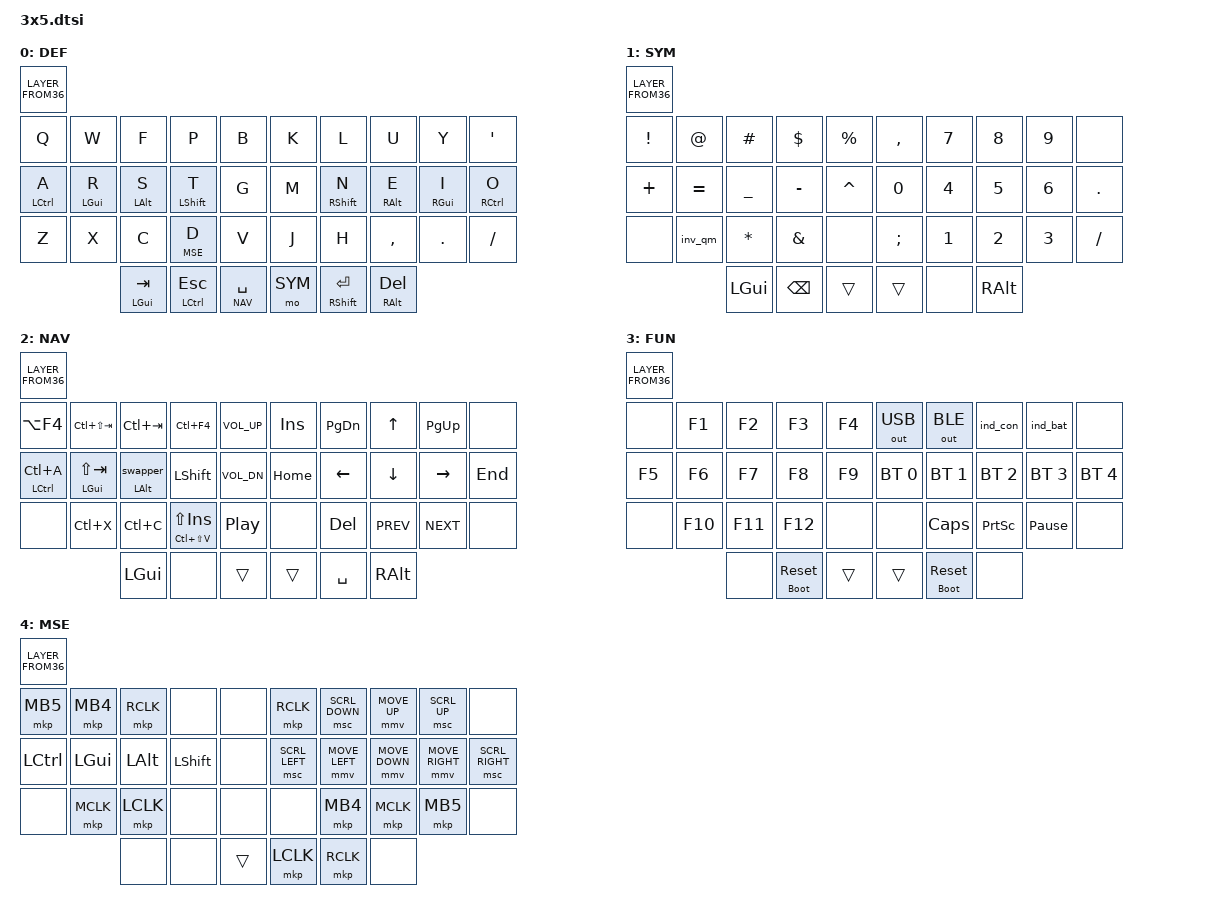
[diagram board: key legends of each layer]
#include <behaviors.dtsi>
#include <dt-bindings/zmk/keys.h>
#include <dt-bindings/zmk/bt.h>
#include <dt-bindings/zmk/outputs.h>

#include <behaviors/rgbled_widget.dtsi>

// Layer aliases
#define DEF 0
#define SYM 1
#define NAV 2
#define FUN 3
#define MSE 4

#include "combos.dtsi"

#include "mouse.dtsi"

&mt {
    flavor = "hold-preferred";
    tapping-term-ms = <150>;
};

&lt {
    flavor = "balanced";
    tapping-term-ms = <150>;
};

&caps_word {
    continue-list = <UNDERSCORE MINUS BSPC DEL N1 N2 N3 N4 N5 N6 N7 N8 N9 N0>;
};

/ {
    behaviors {
        aml: alpha_mods_l {
            compatible = "zmk,behavior-hold-tap";
            #binding-cells = <2>;
            tapping-term-ms = <250>;
            quick-tap-ms = <150>;
            flavor = "balanced";
            bindings = <&kp>, <&kp>;
            hold-trigger-key-positions = <KEYS_R THUMBS>;
            hold-trigger-on-release;
            require-prior-idle-ms = <175>;
        };
        asl: alpha_shift_l {
            compatible = "zmk,behavior-hold-tap";
            #binding-cells = <2>;
            tapping-term-ms = <200>;
            quick-tap-ms = <150>;
            flavor = "balanced";
            bindings = <&kp>, <&kp>;
            hold-trigger-key-positions = <KEYS_R THUMBS>;
            hold-trigger-on-release;
        };
        amr: alpha_mods_r {
            compatible = "zmk,behavior-hold-tap";
            #binding-cells = <2>;
            tapping-term-ms = <250>;
            quick-tap-ms = <150>;
            flavor = "balanced";
            bindings = <&kp>, <&kp>;
            hold-trigger-key-positions = <KEYS_L THUMBS>;
            hold-trigger-on-release;
            require-prior-idle-ms = <175>;
        };
        asr: alpha_shift_r {
            compatible = "zmk,behavior-hold-tap";
            #binding-cells = <2>;
            tapping-term-ms = <200>;
            quick-tap-ms = <150>;
            flavor = "balanced";
            bindings = <&kp>, <&kp>;
            hold-trigger-key-positions = <KEYS_L THUMBS>;
            hold-trigger-on-release;
        };

        // Swapper for smart alt+tab
        swapper: swapper {
            compatible = "zmk,behavior-smart-toggle";
            #binding-cells = <0>;
            bindings = <&kp LALT>, <&kp TAB>;
            ignored-key-positions = <LM3 RM1 RM2 RM3 RT2>;
        };
        ht_sw: ht_sw {
            compatible = "zmk,behavior-hold-tap";
            #binding-cells = <2>;
            tapping-term-ms = <150>;
            flavor = "hold-preferred";
            bindings = <&kp>, <&swapper>;
        };

        rst_boot: rst_boot {
            compatible = "zmk,behavior-hold-tap";
            #binding-cells = <2>;
            tapping-term-ms = <500>;
            flavor = "tap-preferred";
            bindings = <&bootloader>, <&sys_reset>;
        };

        // Strictly timer-based hold-tap, no held keycode
        tpht: tpht {
            compatible = "zmk,behavior-hold-tap";
            #binding-cells = <2>;
            tapping-term-ms = <200>;
            flavor = "tap-preferred";
            bindings = <&ktap>, <&kp>;
        };

        // Mouse layer smart toggle
        mse_tog: mse_tog {
            compatible = "zmk,behavior-smart-toggle";
            #binding-cells = <0>;
            bindings = <&mo MSE>, <&none>;
            ignored-key-positions = <LB3 LB2 LB1 KEYS_R THUMBS>;
        };
    };

    cond_layers {
        compatible = "zmk,conditional-layers";
        // Define FUN layer as tri-state
        func_tristate {
            if-layers = <NAV SYM>;
            then-layer = <FUN>;
        };
    };

    macros {
        ZMK_MACRO(inv_qm,
            wait-ms = <10>;
            tap-ms = <10>;
            bindings
                = <&macro_press &kp LALT>
                , <&macro_tap &kp KP_N1 &kp KP_N6 &kp KP_N8>
                , <&macro_release &kp LALT>;
        )
        ktap: key_tap {
            compatible = "zmk,behavior-macro-one-param";
            #binding-cells = <1>;
            display-name = "Key Tap";
            bindings = <&macro_param_1to1>, <&kp MACRO_PLACEHOLDER>;
            tap-ms = <16>;
        };
    };

    keymap {
        compatible = "zmk,keymap";

        default_layer {
            display-name = "DEF";
            bindings = <LAYER_FROM36( \
// ╭─────────────┬─────────────┬─────────────┬─────────────┬─────────────╮   ╭─────────────┬─────────────┬─────────────┬─────────────┬─────────────╮
     &kp Q,        &kp W,        &kp F,        &kp P,        &kp B,            &kp K,        &kp L,        &kp U,        &kp Y,        &kp SQT,      \
// ├─────────────┼─────────────┼─────────────┼─────────────┼─────────────┤   ├─────────────┼─────────────┼─────────────┼─────────────┼─────────────┤
     &aml LCTRL A, &aml LGUI R,  &aml LALT S,  &asl LSHFT T, &kp G,            &kp M,        &asr RSHFT N, &amr RALT E,  &amr RGUI I,  &amr RCTRL O, \
// ├─────────────┼─────────────┼─────────────┼─────────────┼─────────────┤   ├─────────────┼─────────────┼─────────────┼─────────────┼─────────────┤
     &kp Z,        &kp X,        &kp C,        &lt MSE D,    &kp V,            &kp J,        &kp H,        &kp COMMA,    &kp DOT,      &kp SLASH,    \
// ╰─────────────┴─────────────┴─────────────┼─────────────┼─────────────┤   ├─────────────┼─────────────┼─────────────┴─────────────┴─────────────╯
                                 &mt LGUI TAB, &mt LCTRL ESC, &lt NAV SPACE,   &mo SYM,      &mt RSHFT RET, &mt RALT DEL
//                             ╰─────────────┴─────────────┴─────────────╯   ╰─────────────┴─────────────┴─────────────╯
            )>;
        };

        symbol_layer {
            display-name = "SYM";
            bindings = <LAYER_FROM36( \
// ╭─────────────┬─────────────┬─────────────┬─────────────┬─────────────╮   ╭─────────────┬─────────────┬─────────────┬─────────────┬─────────────╮
     &kp EXCL,     &kp AT,       &kp HASH,     &kp DLLR,     &kp PRCNT,        &kp COMMA,    &kp N7,       &kp N8,       &kp N9,       &none,     \
// ├─────────────┼─────────────┼─────────────┼─────────────┼─────────────┤   ├─────────────┼─────────────┼─────────────┼─────────────┼─────────────┤
     &kp PLUS,     &kp EQUAL,    &kp UNDER,    &kp MINUS,    &kp CARET,        &kp N0,       &kp N4,       &kp N5,       &kp N6,       &kp DOT,   \
// ├─────────────┼─────────────┼─────────────┼─────────────┼─────────────┤   ├─────────────┼─────────────┼─────────────┼─────────────┼─────────────┤
     &none,        &inv_qm,      &kp STAR,     &kp AMPS,     &none,            &kp SEMI,     &kp N1,       &kp N2,       &kp N3,       &kp SLASH, \
// ╰─────────────┴─────────────┴─────────────┼─────────────┼─────────────┤   ├─────────────┼─────────────┼─────────────┴─────────────┴─────────────╯
                                 &kp LGUI,     &kp BSPC,     &trans,           &trans,       &none,        &kp RALT
//                             ╰─────────────┴─────────────┴─────────────╯   ╰─────────────┴─────────────┴─────────────╯
            )>;
        };

        nav_layer {
            display-name = "NAV";
            bindings = <LAYER_FROM36( \
// ╭─────────────┬─────────────┬─────────────┬─────────────┬─────────────╮   ╭─────────────┬─────────────┬─────────────┬─────────────┬─────────────╮
     &kp LA(F4), &kp LC(LS(TAB)), &kp LC(TAB), &kp LC(F4),   &kp C_VOL_UP,     &kp INS,      &kp PG_DN,    &kp UP,       &kp PG_UP,    &none,   \
// ├─────────────┼─────────────┼─────────────┼─────────────┼─────────────┤   ├─────────────┼─────────────┼─────────────┼─────────────┼─────────────┤
 &mt LCTRL LC(A), &mt LGUI LS(TAB), &ht_sw LALT 0, &kp LSHFT, &kp C_VOL_DN,    &kp HOME,     &kp LEFT,     &kp DOWN,     &kp RIGHT,    &kp END, \
// ├─────────────┼─────────────┼─────────────┼─────────────┼─────────────┤   ├─────────────┼─────────────┼─────────────┼─────────────┼─────────────┤
     &none,        &kp LC(X),   &kp LC(C), &tpht LC(LS(V)) LS(INS), &kp C_PP,  &none,        &kp DEL,      &kp C_PREV,   &kp C_NEXT,   &none,   \
// ╰─────────────┴─────────────┴─────────────┼─────────────┼─────────────┤   ├─────────────┼─────────────┼─────────────┴─────────────┴─────────────╯
                                 &kp LGUI,     &none,        &trans,           &trans,       &kp SPACE,    &kp RALT
//                             ╰─────────────┴─────────────┴─────────────╯   ╰─────────────┴─────────────┴─────────────╯
            )>;
        };

        function_layer {
            display-name = "FUN";
            bindings = <LAYER_FROM36( \
// ╭─────────────┬─────────────┬─────────────┬─────────────┬─────────────╮   ╭─────────────┬─────────────┬─────────────┬─────────────┬─────────────╮
     &none,        &kp F1,       &kp F2,       &kp F3,       &kp F4,           &out OUT_USB, &out OUT_BLE, &ind_con,     &ind_bat,     &none,        \
// ├─────────────┼─────────────┼─────────────┼─────────────┼─────────────┤   ├─────────────┼─────────────┼─────────────┼─────────────┼─────────────┤
     &kp F5,       &kp F6,       &kp F7,       &kp F8,       &kp F9,           &bt BT_SEL 0, &bt BT_SEL 1, &bt BT_SEL 2, &bt BT_SEL 3, &bt BT_SEL 4, \
// ├─────────────┼─────────────┼─────────────┼─────────────┼─────────────┤   ├─────────────┼─────────────┼─────────────┼─────────────┼─────────────┤
     &none,        &kp F10,      &kp F11,      &kp F12,      &none,            &none,        &kp CAPS,     &kp PSCRN,   &kp PAUSE_BREAK, &none,      \
// ╰─────────────┴─────────────┴─────────────┼─────────────┼─────────────┤   ├─────────────┼─────────────┼─────────────┴─────────────┴─────────────╯
                                 &none,        &rst_boot 0 0, &trans,          &trans,       &rst_boot 0 0, &none
//                             ╰─────────────┴─────────────┴─────────────╯   ╰─────────────┴─────────────┴─────────────╯
            )>;
        };

        mouse_layer {
            display-name = "MSE";
            bindings = <LAYER_FROM36( \
// ╭─────────────┬─────────────┬─────────────┬─────────────┬─────────────╮   ╭─────────────┬─────────────┬─────────────┬─────────────┬─────────────╮
     &mkp MB5,     &mkp MB4,     &mkp RCLK,    &none,        &none,            &mkp RCLK,  &msc SCRL_DOWN, &mmv MOVE_UP, &msc SCRL_UP, &none,                \
// ├─────────────┼─────────────┼─────────────┼─────────────┼─────────────┤   ├─────────────┼─────────────┼─────────────┼─────────────┼─────────────┤
     &kp LCTRL,    &kp LGUI,     &kp LALT,     &kp LSHFT,    &none,        &msc SCRL_LEFT, &mmv MOVE_LEFT, &mmv MOVE_DOWN, &mmv MOVE_RIGHT, &msc SCRL_RIGHT, \
// ├─────────────┼─────────────┼─────────────┼─────────────┼─────────────┤   ├─────────────┼─────────────┼─────────────┼─────────────┼─────────────┤
     &none,        &mkp MCLK,    &mkp LCLK,    &none,        &none,            &none,        &mkp MB4,     &mkp MCLK,    &mkp MB5,     &none,                \
// ╰─────────────┴─────────────┴─────────────┼─────────────┼─────────────┤   ├─────────────┼─────────────┼─────────────┴─────────────┴─────────────╯
                                 &none,        &none,        &trans,           &mkp LCLK,    &mkp RCLK,    &none                                             \
//                             ╰─────────────┴─────────────┴─────────────╯   ╰─────────────┴─────────────┴─────────────╯
            )>;
        };
    };
};
